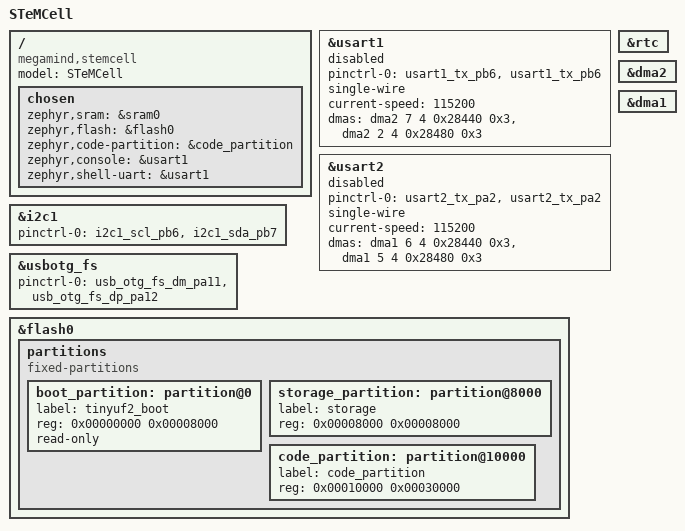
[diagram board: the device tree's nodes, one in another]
/*
 * Copyright (c) 2022 Mega Mind
 *
 * SPDX-License-Identifier: MIT
 */

/dts-v1/;
#include <st/f4/stm32f401Xc.dtsi>
#include <st/f4/stm32f401c(b-c)ux-pinctrl.dtsi>

#include "pro_micro.dtsi"

/ {
	model = "STeMCell";
	compatible = "megamind,stemcell", "st,stm32f401";

	chosen {
		zephyr,sram = &sram0;
		zephyr,flash = &flash0;
		zephyr,code-partition = &code_partition;
		zephyr,console = &usart1;
		zephyr,shell-uart = &usart1;
	};
};

&usart1 {
	pinctrl-0 = <&usart1_tx_pb6 &usart1_tx_pb6>;
	single-wire;
	current-speed = <115200>;
	dmas = <&dma2 7 4 0x28440 0x3  &dma2 2 4 0x28480 0x3>;
	dma-names = "tx", "rx";
	status = "disabled";
};

&usart2 {
	pinctrl-0 = <&usart2_tx_pa2 &usart2_tx_pa2>;
	single-wire;
	current-speed = <115200>;
	dmas = <&dma1 6 4 0x28440 0x3  &dma1 5 4 0x28480 0x3>;
	dma-names = "tx", "rx";
	status = "disabled";
};

&i2c1 {
	pinctrl-0 = <&i2c1_scl_pb6 &i2c1_sda_pb7>;
};

&usbotg_fs {
	pinctrl-0 = <&usb_otg_fs_dm_pa11 &usb_otg_fs_dp_pa12>;
	status = "okay";
};

&rtc {
	status = "okay";
};

&dma2 {
	status = "okay";
};

&dma1 {
	status = "okay";
};

&flash0 {
	/*
	 * For more information, see:
	 * http://docs.zephyrproject.org/latest/guides/dts/index.html#flash-partitions
	 */
	partitions {
		compatible = "fixed-partitions";
		#address-cells = <1>;
		#size-cells = <1>;

		boot_partition: partition@0 {
			label = "tinyuf2_boot";
			reg = <0x00000000 0x00008000>;
			read-only;
		};

		storage_partition: partition@8000 {
		   label = "storage";
		   reg = <0x00008000 0x00008000>;
	   };

		code_partition: partition@10000 {
			label = "code_partition";
			reg = <0x00010000 0x00030000>;
		};
	};
};
